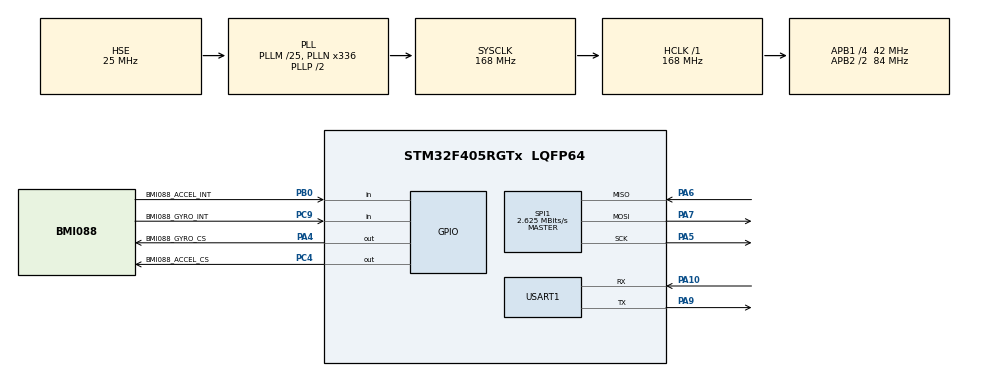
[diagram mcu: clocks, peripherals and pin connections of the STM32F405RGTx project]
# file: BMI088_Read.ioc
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FREERTOS.Tasks01=imuTask,24,512,StartImuTask,Default,NULL,Dynamic,NULL,NULL
FREERTOS.configTOTAL_HEAP_SIZE=10240
Mcu.Family=STM32F4
Mcu.Name=STM32F405RGTx
Mcu.Package=LQFP64
NVIC.PriorityGroup=NVIC_PRIORITYGROUP_4
NVIC.TIM2_IRQn=true\:15\:0\:false\:false\:true\:false\:false\:true\:true
NVIC.TimeBase=TIM2_IRQn
NVIC.TimeBaseIP=TIM2
PA10.Mode=Asynchronous
PA10.Signal=USART1_RX
PA13.Mode=Serial_Wire
PA13.Signal=SYS_JTMS-SWDIO
PA14.Mode=Serial_Wire
PA14.Signal=SYS_JTCK-SWCLK
PA4.GPIO_Label=BMI088_GYRO_CS
PA4.PinState=GPIO_PIN_SET
PA4.Signal=GPIO_Output
PA5.Mode=Full_Duplex_Master
PA5.Signal=SPI1_SCK
PA6.Mode=Full_Duplex_Master
PA6.Signal=SPI1_MISO
PA7.Mode=Full_Duplex_Master
PA7.Signal=SPI1_MOSI
PA9.Mode=Asynchronous
PA9.Signal=USART1_TX
PB0.GPIO_Label=BMI088_ACCEL_INT
PB0.Signal=GPIO_Input
PC4.GPIO_Label=BMI088_ACCEL_CS
PC4.PinState=GPIO_PIN_SET
PC4.Signal=GPIO_Output
PC9.GPIO_Label=BMI088_GYRO_INT
PC9.Signal=GPIO_Input
PH0-OSC_IN.Mode=HSE-External-Oscillator
PH0-OSC_IN.Signal=RCC_OSC_IN
PH1-OSC_OUT.Mode=HSE-External-Oscillator
PH1-OSC_OUT.Signal=RCC_OSC_OUT
ProjectManager.HeapSize=0x200
ProjectManager.StackSize=0x400
ProjectManager.TargetToolchain=MDK-ARM V5.32
RCC.48MHZClocksFreq_Value=84000000
RCC.AHBFreq_Value=168000000
RCC.APB1CLKDivider=RCC_HCLK_DIV4
RCC.APB1Freq_Value=42000000
RCC.APB1TimFreq_Value=84000000
RCC.APB2CLKDivider=RCC_HCLK_DIV2
RCC.APB2Freq_Value=84000000
RCC.APB2TimFreq_Value=168000000
RCC.CortexFreq_Value=168000000
RCC.HCLKFreq_Value=168000000
RCC.HSE_VALUE=25000000
RCC.HSI_VALUE=16000000
RCC.LSE_VALUE=32768
RCC.PLLM=25
RCC.PLLN=336
RCC.PLLSourceVirtual=RCC_PLLSOURCE_HSE
RCC.SYSCLKFreq_VALUE=168000000
RCC.SYSCLKSource=RCC_SYSCLKSOURCE_PLLCLK
RCC.VCOOutputFreq_Value=336000000
SPI1.BaudRatePrescaler=SPI_BAUDRATEPRESCALER_32
SPI1.CalculateBaudRate=2.625 MBits/s
SPI1.Direction=SPI_DIRECTION_2LINES
SPI1.Mode=SPI_MODE_MASTER
SPI1.VirtualType=VM_MASTER
USART1.VirtualMode=VM_ASYNC
VP_FREERTOS_VS_CMSIS_V2.Mode=CMSIS_V2
VP_SYS_VS_tim2.Mode=TIM2
board=custom

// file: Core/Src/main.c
/* USER CODE BEGIN Header */
/**
  ******************************************************************************
  * @file           : main.c
  * @brief          : Main program body
  ******************************************************************************
  * @attention
  *
  * Copyright (c) 2026 STMicroelectronics.
  * All rights reserved.
  *
  * This software is licensed under terms that can be found in the LICENSE file
  * in the root directory of this software component.
  * If no LICENSE file comes with this software, it is provided AS-IS.
  *
  ******************************************************************************
  */
/* USER CODE END Header */
#include "main.h"
#include "cmsis_os.h"
#include "spi.h"
#include "usart.h"
#include "gpio.h"

void SystemClock_Config(void);
void MX_FREERTOS_Init(void);

int main(void)
{

  /* MCU Configuration--------------------------------------------------------*/

  /* Reset of all peripherals, Initializes the Flash interface and the Systick. */
  HAL_Init();

  /* Configure the system clock */
  SystemClock_Config();

  /* Initialize all configured peripherals */
  MX_GPIO_Init();
  MX_SPI1_Init();
  MX_USART1_UART_Init();

  /* Init scheduler */
  osKernelInitialize();  /* Call init function for freertos objects (in cmsis_os2.c) */
  MX_FREERTOS_Init();

  /* Start scheduler */
  osKernelStart();

  /* We should never get here as control is now taken by the scheduler */

  /* Infinite loop */
  while (1)
  {

  }
}

void SystemClock_Config(void)
{
  RCC_OscInitTypeDef RCC_OscInitStruct = {0};
  RCC_ClkInitTypeDef RCC_ClkInitStruct = {0};

  /** Configure the main internal regulator output voltage
  */
  __HAL_RCC_PWR_CLK_ENABLE();
  __HAL_PWR_VOLTAGESCALING_CONFIG(PWR_REGULATOR_VOLTAGE_SCALE1);

  /** Initializes the RCC Oscillators according to the specified parameters
  * in the RCC_OscInitTypeDef structure.
  */
  RCC_OscInitStruct.OscillatorType = RCC_OSCILLATORTYPE_HSE;
  RCC_OscInitStruct.HSEState = RCC_HSE_ON;
  RCC_OscInitStruct.PLL.PLLState = RCC_PLL_ON;
  RCC_OscInitStruct.PLL.PLLSource = RCC_PLLSOURCE_HSE;
  RCC_OscInitStruct.PLL.PLLM = 25;
  RCC_OscInitStruct.PLL.PLLN = 336;
  RCC_OscInitStruct.PLL.PLLP = RCC_PLLP_DIV2;
  RCC_OscInitStruct.PLL.PLLQ = 4;
  if (HAL_RCC_OscConfig(&RCC_OscInitStruct) != HAL_OK)
  {
    Error_Handler();
  }

  /** Initializes the CPU, AHB and APB buses clocks
  */
  RCC_ClkInitStruct.ClockType = RCC_CLOCKTYPE_HCLK|RCC_CLOCKTYPE_SYSCLK
                              |RCC_CLOCKTYPE_PCLK1|RCC_CLOCKTYPE_PCLK2;
  RCC_ClkInitStruct.SYSCLKSource = RCC_SYSCLKSOURCE_PLLCLK;
  RCC_ClkInitStruct.AHBCLKDivider = RCC_SYSCLK_DIV1;
  RCC_ClkInitStruct.APB1CLKDivider = RCC_HCLK_DIV4;
  RCC_ClkInitStruct.APB2CLKDivider = RCC_HCLK_DIV2;

  if (HAL_RCC_ClockConfig(&RCC_ClkInitStruct, FLASH_LATENCY_5) != HAL_OK)
  {
    Error_Handler();
  }
}

void HAL_TIM_PeriodElapsedCallback(TIM_HandleTypeDef *htim)
{
  if (htim->Instance == TIM2)
  {
    HAL_IncTick();
  }
}

void Error_Handler(void)
{
  __disable_irq();
  while (1)
  {
  }
}

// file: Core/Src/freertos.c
/* USER CODE BEGIN Header */
/**
  ******************************************************************************
  * File Name          : freertos.c
  * Description        : Code for freertos applications
  ******************************************************************************
  * @attention
  *
  * Copyright (c) 2026 STMicroelectronics.
  * All rights reserved.
  *
  * This software is licensed under terms that can be found in the LICENSE file
  * in the root directory of this software component.
  * If no LICENSE file comes with this software, it is provided AS-IS.
  *
  ******************************************************************************
  */
/* USER CODE END Header */

#include "FreeRTOS.h"
#include "task.h"
#include "main.h"
#include "cmsis_os.h"

/* USER CODE BEGIN Includes */
#include "imu_app.h" /* 分模块业务入口：BMI088、校准、Mahony 和 VOFA。 */
/* USER CODE END Includes */

/* Definitions for imuTask */
osThreadId_t imuTaskHandle;
const osThreadAttr_t imuTask_attributes = {
  .name = "imuTask",
  .stack_size = 512 * 4, /* CubeMX 的 512 words 换成 CMSIS v2 的 2048 字节。 */
  .priority = (osPriority_t) osPriorityNormal, /* 正常优先级；周期等待时释放 CPU。 */
};

void StartImuTask(void *argument);

void MX_FREERTOS_Init(void); /* (MISRA C 2004 rule 8.1) */

void MX_FREERTOS_Init(void) {

  /* Create the thread(s) */
  /* creation of imuTask */
  imuTaskHandle = osThreadNew(StartImuTask, NULL, &imuTask_attributes); /* 动态分配 IMU 任务。 */

  /* USER CODE BEGIN RTOS_THREADS */
  if (imuTaskHandle == NULL)
  {
    Error_Handler(); /* 堆不足等创建失败不能被当作正常启动。 */
  }
  /* USER CODE END RTOS_THREADS */

}

void StartImuTask(void *argument)
{
  /* USER CODE BEGIN StartImuTask */
  (void)argument; /* 此任务不需要外部启动参数。 */
  ImuApp_Run(); /* 全部业务由 App 模块负责；正常运行时本函数不返回。 */
  /* USER CODE END StartImuTask */
}
